# K1921VK01T register map
Vendor: NIIET; Series: K1921VKx; File version: 2.2
CPU: CM4 r0p1, little endian, MPU, FPU, 3 interrupt priority bits
Registers are 32-bit, read-write, reset 0x0 unless marked. A register's access mark holds for its fields unless they carry their own. Offsets are from the block's base; [hi:lo] are bit positions; lines under a group give offsets from that group; {n}, {i} and the like mark numbered series.

## NT_USBDevice — USB Device controller registers
Base 0x80090000; alternate view of NT_USBHost
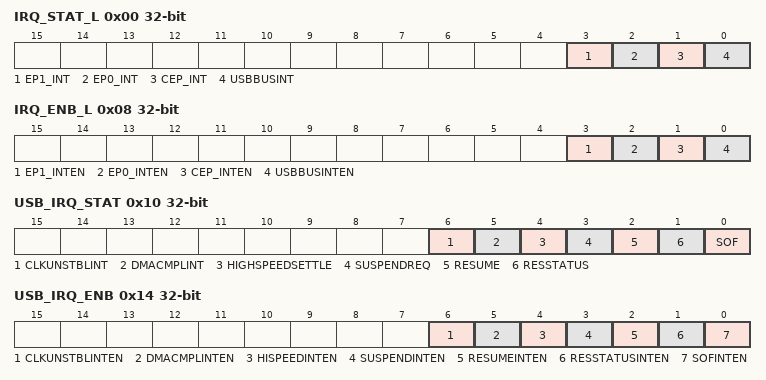
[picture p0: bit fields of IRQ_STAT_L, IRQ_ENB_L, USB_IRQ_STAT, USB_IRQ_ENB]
0x00 IRQ_STAT_L — Interrupt status register
  [3] EP1_INT — Interrupt flags EndPoint 2
  [2] EP0_INT — Interrupt flags EndPoint 1
  [1] CEP_INT — Interrupt flag Control EndPoint
  [0] USBBUSINT — Interrupt flag events on the USB bus
0x08 IRQ_ENB_L — Interrupt enable register
  [3] EP1_INTEN — Interrupt enable for EndPoint 2
  [2] EP0_INTEN — Interrupt enable for EndPoint 1
  [1] CEP_INTEN — Interrupt enable for Control EndPoint
  [0] USBBUSINTEN — Enable interrupts from the events on the USB bus
0x10 USB_IRQ_STAT — USB Interrupt status register
  [6] CLKUNSTBLINT — Interrupt flag, signaling an unstable clock signal UTMI and to initialize the device controller registers
  [5] DMACMPLINT — Completion flag DMA data transfer
  [4] HIGHSPEEDSETTLE — Completion flag reset and switching devices in high-speed mode
  [3] SUSPENDREQ — SUSPEND mode request bit
  [2] RESUME — Flag reactivate the device
  [1] RESSTATUS — Completion flag reset the root port
  [0] SOF — Flag SOF packet reception
0x14 USB_IRQ_ENB — USB Interrupt enable register
  [6] CLKUNSTBLINTEN — Enable interrupt, signaling an unstable clock signal UTMI and to initialize the device controller registers
  [5] DMACMPLINTEN — Enable completion DMA data transfer
  [4] HISPEEDINTEN — Enable completion reset and switching devices in high-speed mode
  [3] SUSPENDINTEN — Enable SUSPEND mode request bit
  [2] RESUMEINTEN — Enable reactivate the device
  [1] RESSTATUSINTEN — Enable completion reset the root port
  [0] SOFINTEN — Enable SOF packet reception
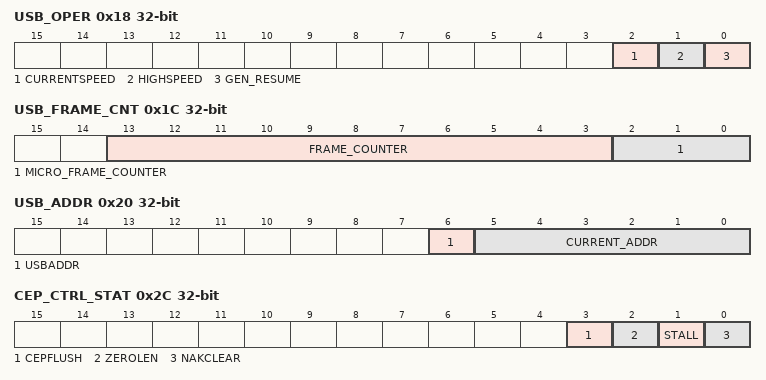
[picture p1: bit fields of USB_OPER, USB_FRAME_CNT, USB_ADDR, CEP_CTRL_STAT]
0x18 USB_OPER — USB Operations register
  [2] CURRENTSPEED — Speed indication device controller 1-High speed; 0 - Full speed
  [1] HIGHSPEED — Trigger bit protocol 'Chirp'
  [0] GEN_RESUME — Bit start recovery work
0x1C USB_FRAME_CNT ro — USB Frame counter register
  [13:3] FRAME_COUNTER — Field frame counter since last SOF packet
  [2:0] MICRO_FRAME_COUNTER — Number field current a chip
0x20 USB_ADDR — USB Address register
  [6] USBADDR — Field of the current address of the device
  [5:0] CURRENT_ADDR — Field of the current address of the device
0x28 CEP_DATA_BUF — Data buffer for transmission register of Control EndPoint
  [15:0] DATA_BUF — Data buffer for transmission
0x2C CEP_CTRL_STAT — Control register and buffer status of Control EndPoint
  [3] CEPFLUSH — Reset buffer
  [2] ZEROLEN — Enable transmission zero length packet
  [1] STALL — Enable sending 'Stall'
  [0] NAKCLEAR — Receiving flag tags SETIP
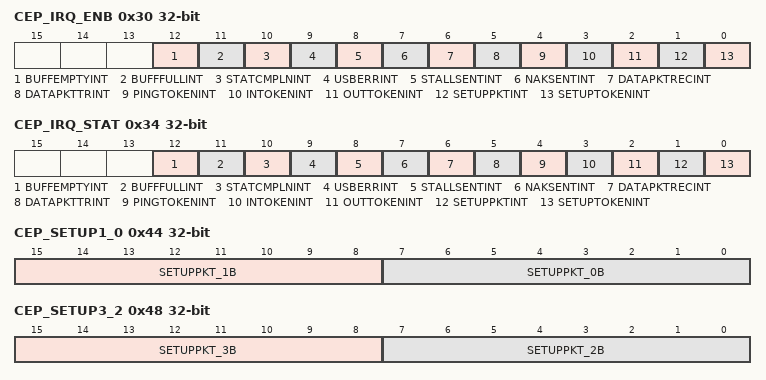
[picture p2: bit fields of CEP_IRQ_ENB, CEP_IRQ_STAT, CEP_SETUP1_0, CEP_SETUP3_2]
0x30 CEP_IRQ_ENB — Interrupt Enable buffer register of Control EndPoint
  [12] BUFFEMPTYINT — Enable flag emptying control buffer
  [11] BUFFFULLINT — Enable flag filling control buffer
  [10] STATCMPLNINT — Enable flag successful completion stage 'Status' operations on the USB bus
  [9] USBERRINT — Enable error flag during the operation
  [8] STALLSENTINT — Enable flag closure parcel labels STALL in response to mark IN or OUT
  [7] NAKSENTINT — Enable flag closure parcel labels NAK in response to mark IN or OUT
  [6] DATAPKTRECINT — Enable flag successful reception of the data packet following the label OUT, in response to which the mark has been sent ACK
  [5] DATAPKTTRINT — Enable flag successful sending of the data packet in response to the label to obtain IN ACK confirming tags
  [4] PINGTOKENINT — Enable reception end flag tags PING from host
  [3] INTOKENINT — Enable reception end flag tags IN from the host
  [2] OUTTOKENINT — Enable reception end flag tags OUT from the host
  [1] SETUPPKTINT — Enable flag deadline Setup package from the host
  [0] SETUPTOKENINT — Enable flag deadline tags SETUP from the host
0x34 CEP_IRQ_STAT — Buffer interrupt flag register of Control EndPoint
  [12] BUFFEMPTYINT ro — Flag control buffer emptying
  [11] BUFFFULLINT ro — Flag filling control buffer
  [10] STATCMPLNINT — Flag successful completion stage 'Status' operations on the USB bus
  [9] USBERRINT — The error flag during the operation
  [8] STALLSENTINT — Flag closure parcel labels STALL in response to mark IN or OUT
  [7] NAKSENTINT — Flag closure parcel labels NAK in response to mark IN or OUT
  [6] DATAPKTRECINT — Flag successful reception of the data packet following the label OUT, in response to which the mark has been sent ACK
  [5] DATAPKTTRINT — Flag successful sending of the data packet in response to the label to obtain IN ACK confirming tags
  [4] PINGTOKENINT — Reception end flag tags PING from host
  [3] INTOKENINT — Reception end flag tags IN from the host
  [2] OUTTOKENINT — Reception end flag tags OUT from the host
  [1] SETUPPKTINT — Flag deadline Setup package from the host
  [0] SETUPTOKENINT — Flag deadline tags SETUP from the host
0x38 CEP_IN_XFRCNT — In transfer data count register of Control EndPoint
  [15:0] DATACOUNT — The number of bytes to be sent in response to a label IN
0x3C CEP_OUT_XFRCNT ro — Out-transfer data count register of Control EndPoint
  [15:0] DATACOUNT — The number of bytes received of data
0x44 CEP_SETUP1_0 ro — Register zero and first byte packet Setup of Control EndPoint
  [15:8] SETUPPKT_1B — The first byte of the packet Setup
  [7:0] SETUPPKT_0B — destination
0x48 CEP_SETUP3_2 ro — Register 2nd and 3rd bytes of the packet Setup of Control EndPoint
  [15:8] SETUPPKT_3B — High byte field wValue
  [7:0] SETUPPKT_2B — Low byte field wValue
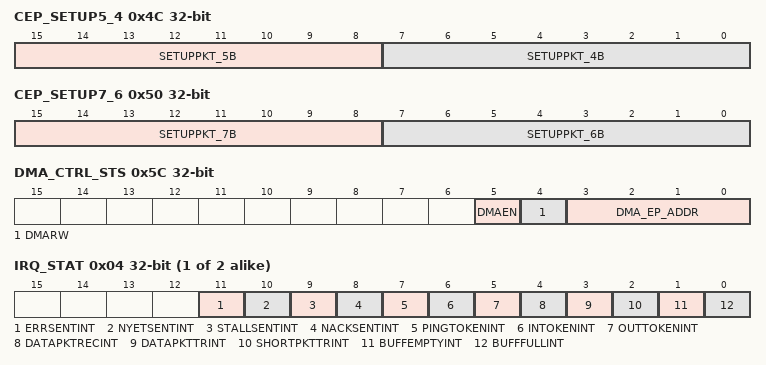
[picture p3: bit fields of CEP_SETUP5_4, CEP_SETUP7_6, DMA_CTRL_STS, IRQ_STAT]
0x4C CEP_SETUP5_4 ro — Register 4th and 5th bytes of the packet Setup of Control EndPoint
  [15:8] SETUPPKT_5B — High byte field windex
  [7:0] SETUPPKT_4B — Low byte field windex
0x50 CEP_SETUP7_6 ro — Register on the 6th and 7th byte packet Setup of Control EndPoint
  [15:8] SETUPPKT_7B — High byte field wLength
  [7:0] SETUPPKT_6B — Low byte field wLength
0x54 CEP_START_ADDR — Control EndPoint RAM start Addr register
  [15:0] STARTADDR
0x58 CEP_END_ADDR — Control EndPoint RAM end Addr register
  [15:0] ENDADDR
0x5C DMA_CTRL_STS — Register control DMA
  [5] DMAEN — Enable DMA
  [4] DMARW — Type DMA operations 1-Read, 0-Write
  [3:0] DMA_EP_ADDR
0x60 DMA_CNT — DMA Count byte Register
  [15:0] DMA_CNT
{0x64+0x28*i} USB_EP[{i}] (i=0..1) group
  0x00 DATA_BUF — EndPoint Data Register
    [15:0] DATA
  0x04 IRQ_STAT — Interrupt flag register no control buffer
    [11] ERRSENTINT — Flag of any error during the operation
    [10] NYETSENTINT — Flag lack of free memory to receive the next data packet
    [9] STALLSENTINT — Flag Uncommitted last packet
    [8] NACKSENTINT — Flag unsent last packet
    [7] PINGTOKENINT — Receiving flag tags PING from the host
    [6] INTOKENINT — Receiving flag tags IN from the host
    [5] OUTTOKENINT — Receiving flag tags OUT from the host
    [4] DATAPKTRECINT — Flag successful reception of a data packet from a host
    [3] DATAPKTTRINT — Flag to send a data packet from the buffer to the host
    [2] SHORTPKTTRINT — Flag size of the last packet
    [1] BUFFEMPTYINT ro — Buffer empty flag
    [0] BUFFFULLINT ro — Flag buffer fill
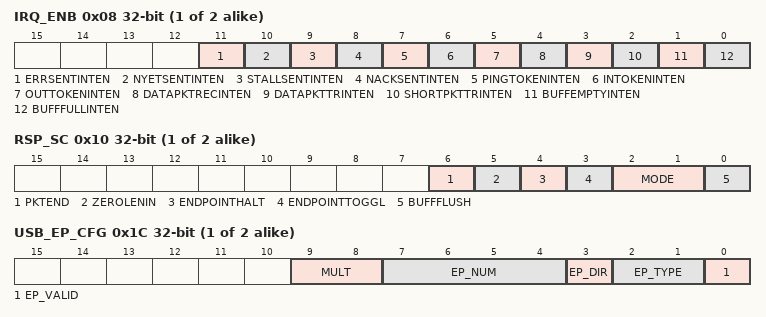
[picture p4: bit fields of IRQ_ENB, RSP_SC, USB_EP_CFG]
  0x08 IRQ_ENB — Enable register Interrupt no control buffer
    [11] ERRSENTINTEN — Enable flag of any error during the operation
    [10] NYETSENTINTEN — Enable flag lack of free memory to receive the next data packet
    [9] STALLSENTINTEN — Enable flag Uncommitted last packet
    [8] NACKSENTINTEN — Enable flag unsent last packet
    [7] PINGTOKENINTEN — Enable receiving flag tags PING from the host
    [6] INTOKENINTEN — Enable receiving flag tags IN from the host
    [5] OUTTOKENINTEN — Enable receiving flag tags OUT from the host
    [4] DATAPKTRECINTEN — Enable flag successful reception of a data packet from a host
    [3] DATAPKTTRINTEN — Enable flag to send a data packet from the buffer to the host
    [2] SHORTPKTTRINTEN — Enable flag size of the last packet
    [1] BUFFEMPTYINTEN — Enable buffer empty flag
    [0] BUFFFULLINTEN — Enable flag buffer fill
  0x0C AVAIL_CNT ro — EndPoint Available count register
    [11:0] BUFFBYTENUM — Number of bytes in the buffer
  0x10 RSP_SC — EndPoint Response Set/Clear register
    [6] PKTEND — Indicator number of bytes
    [5] ZEROLENIN — Select bit answer to mark IN
    [4] ENDPOINTHALT — Select bit answer to any label from the host
    [3] ENDPOINTTOGGL — Control bit by bit DATATOGGLE
    [2:1] MODE
    [0] BUFFFLUSH — Reset bit in the buffer and register EP_AVAIL_CNT
  0x14 MPS — EndPoint maximum packet size register
    [15:0] MAXPKTSIZE
  0x18 CNT — EndPoint Transfer count register
    [7:0] EP_TFR_CNT
  0x1C USB_EP_CFG — EndPoint configuration register
    [9:8] MULT
      0=1 operation; 1=2 operation; 2=3 operation
    [7:4] EP_NUM — Number field buffer
    [3] EP_DIR — Field of type (direction) buffer
      0=OUT; 1=IN
    [2:1] EP_TYPE
      1=Bulk; 2=Int (Interrupt); 3=Isochronous
    [0] EP_VALID — Resolution of buffer
  0x20 START_ADDR — EndPoint RAM start addres register
    [15:0] STARTADDR
  0x24 END_ADDR — EndPoint RAM end addres register
    [15:0] ENDADDR
0x700 AHB_DMA_ADDR — AHB addr register
  [31:0] AHBADDR — It specifies the address from which the DMA has to read / write.The address must WORD (32- bits) aligned
